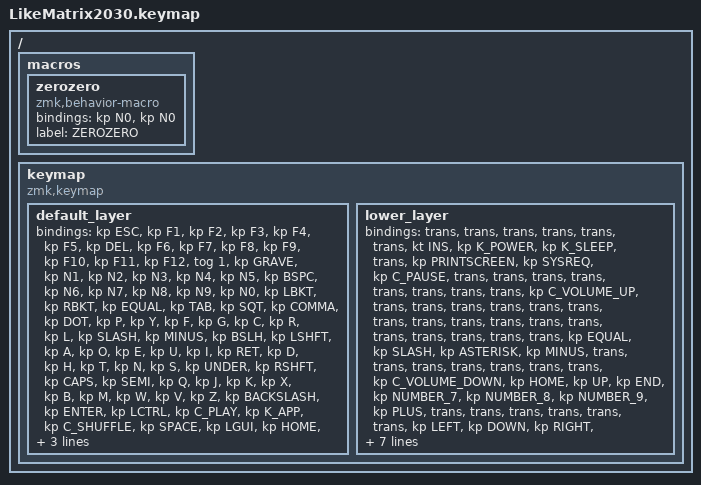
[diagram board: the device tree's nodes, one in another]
#include <behaviors.dtsi>
#include <dt-bindings/zmk/keys.h>

/ {
    macros {
        zerozero: zerozero {
            compatible = "zmk,behavior-macro";
            #binding-cells = <0>;
            bindings = <&kp N0 &kp N0>;
            label = "ZEROZERO";
        };
    };

    keymap {
        compatible = "zmk,keymap";

        default_layer {
            bindings = <
&kp ESC  &kp F1  &kp F2  &kp F3  &kp F4  &kp F5  &kp DEL  &kp F6  &kp F7  &kp F8  &kp F9  &kp F10  &kp F11  &kp F12  &tog 1  &kp GRAVE  &kp N1  &kp N2  &kp N3  &kp N4  &kp N5  &kp BSPC  &kp N6  &kp N7  &kp N8  &kp N9  &kp N0  &kp LBKT  &kp RBKT  &kp EQUAL  &kp TAB  &kp SQT  &kp COMMA  &kp DOT  &kp P  &kp Y  &kp F  &kp G  &kp C  &kp R  &kp L  &kp SLASH  &kp MINUS  &kp BSLH  &kp LSHFT  &kp A  &kp O  &kp E  &kp U  &kp I  &kp RET  &kp D  &kp H  &kp T  &kp N  &kp S  &kp UNDER  &kp RSHFT  &kp CAPS  &kp SEMI  &kp Q  &kp J  &kp K  &kp X  &kp B  &kp M  &kp W  &kp V  &kp Z  &kp BACKSLASH  &kp ENTER  &kp LCTRL  &kp C_PLAY  &kp K_APP  &kp C_SHUFFLE  &kp SPACE  &kp LGUI  &kp HOME  &kp UP  &kp END  &kp RCTRL  &kp PG_UP  &mo 1  &kp LWIN  &kp LALT  &kp RALT  &kp LEFT  &kp DOWN  &kp RIGHT  &kp PG_DN
            >;
        };

        lower_layer {
            bindings = <
&trans  &trans  &trans  &trans  &trans  &trans  &kt INS  &kp K_POWER  &kp K_SLEEP  &trans  &kp PRINTSCREEN  &kp SYSREQ  &kp C_PAUSE  &trans  &trans  &trans  &trans  &trans  &trans  &trans  &trans  &kp C_VOLUME_UP  &trans  &trans  &trans  &trans  &trans  &trans  &trans  &trans  &trans  &trans  &trans  &trans  &trans  &trans  &trans  &trans  &trans  &kp EQUAL  &kp SLASH  &kp ASTERISK  &kp MINUS  &trans  &trans  &trans  &trans  &trans  &trans  &trans  &kp C_VOLUME_DOWN  &kp HOME  &kp UP  &kp END  &kp NUMBER_7  &kp NUMBER_8  &kp NUMBER_9  &kp PLUS  &trans  &trans  &trans  &trans  &trans  &trans  &kp LEFT  &kp DOWN  &kp RIGHT  &kp NUMBER_4  &kp NUMBER_5  &kp NUMBER_6  &trans  &trans  &kp K_CUT  &kp K_COPY  &kp K_PASTE  &kp K_MUTE  &kp PAGE_UP  &kp NUMBER_1  &kp NUMBER_2  &kp NUMBER_3  &kp ENTER  &trans  &trans  &trans  &trans  &kp PAGE_DOWN  &kp NUMBER_0  &zerozero  &kp PERIOD  &trans
            >;
        };
    };
};
